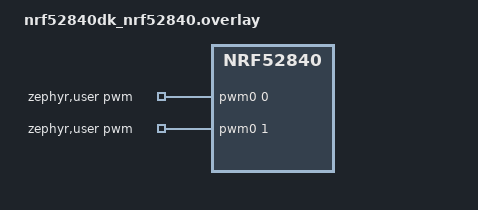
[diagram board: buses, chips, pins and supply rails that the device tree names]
/*
 * Copyright (c) 2026 Nordic Semiconductor ASA
 *
 * SPDX-License-Identifier: LicenseRef-Nordic-5-Clause
 */

/ {
	zephyr,user {
		pwms = <&pwm0 0 16000000 PWM_POLARITY_NORMAL>,
		       <&pwm0 1 16000000 PWM_POLARITY_NORMAL>;
	};
};
